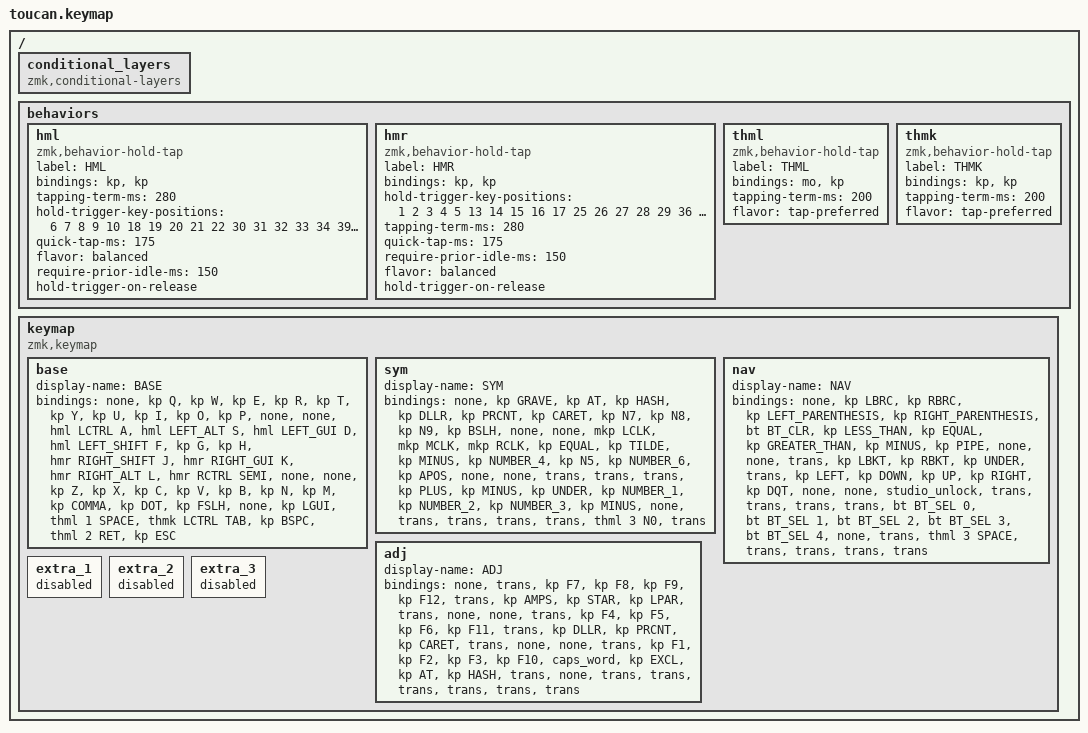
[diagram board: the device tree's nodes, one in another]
#include <behaviors.dtsi>
#include <dt-bindings/zmk/bt.h>
#include <dt-bindings/zmk/keys.h>
#include <dt-bindings/zmk/pointing.h>

#define BASE 0
#define NAV  1
#define SYM  2
#define ADJ  3

/ {
    conditional_layers { compatible = "zmk,conditional-layers"; };

    behaviors {
        hml: hml {
            compatible = "zmk,behavior-hold-tap";
            label = "HML";
            bindings = <&kp>, <&kp>;

            #binding-cells = <2>;
            tapping-term-ms = <280>;
            hold-trigger-key-positions = <6 7 8 9 10 18 19 20 21 22 30 31 32 33 34 39 40 41>;
            quick-tap-ms = <175>;
            flavor = "balanced";
            require-prior-idle-ms = <150>;
            hold-trigger-on-release;
        };

        hmr: hmr {
            compatible = "zmk,behavior-hold-tap";
            label = "HMR";
            bindings = <&kp>, <&kp>;

            #binding-cells = <2>;
            hold-trigger-key-positions = <1 2 3 4 5 13 14 15 16 17 25 26 27 28 29 36 37 38>;
            tapping-term-ms = <280>;
            quick-tap-ms = <175>;
            require-prior-idle-ms = <150>;
            flavor = "balanced";
            hold-trigger-on-release;
        };

        thml: thml {
            compatible = "zmk,behavior-hold-tap";
            label = "THML";
            bindings = <&mo>, <&kp>;

            #binding-cells = <2>;
            tapping-term-ms = <200>;
            flavor = "tap-preferred";
        };

        thmk: thmk {
            compatible = "zmk,behavior-hold-tap";
            label = "THMK";
            bindings = <&kp>, <&kp>;

            #binding-cells = <2>;
            tapping-term-ms = <200>;
            flavor = "tap-preferred";
        };
    };

    keymap {
        compatible = "zmk,keymap";

        base {
            display-name = "BASE";
            bindings = <
&none  &kp Q  &kp W  &kp E  &kp R  &kp T  &kp Y  &kp U  &kp I  &kp O  &kp P  &none  &none  &hml LCTRL A  &hml LEFT_ALT S  &hml LEFT_GUI D  &hml LEFT_SHIFT F  &kp G  &kp H  &hmr RIGHT_SHIFT J  &hmr RIGHT_GUI K  &hmr RIGHT_ALT L  &hmr RCTRL SEMI  &none  &none  &kp Z  &kp X  &kp C  &kp V  &kp B  &kp N  &kp M  &kp COMMA  &kp DOT  &kp FSLH  &none  &kp LGUI  &thml 1 SPACE  &thmk LCTRL TAB  &kp BSPC  &thml 2 RET  &kp ESC
            >;
        };

        sym {
            display-name = "SYM";
            bindings = <
&none  &kp GRAVE  &kp AT  &kp HASH  &kp DLLR  &kp PRCNT  &kp CARET  &kp N7  &kp N8  &kp N9  &kp BSLH  &none  &none  &mkp LCLK  &mkp MCLK  &mkp RCLK  &kp EQUAL  &kp TILDE  &kp MINUS  &kp NUMBER_4  &kp N5  &kp NUMBER_6  &kp APOS  &none  &none  &trans  &trans  &trans  &kp PLUS  &kp MINUS  &kp UNDER  &kp NUMBER_1  &kp NUMBER_2  &kp NUMBER_3  &kp MINUS  &none  &trans  &trans  &trans  &trans  &thml 3 N0  &trans
            >;
        };

        nav {
            display-name = "NAV";
            bindings = <
&none  &kp LBRC  &kp RBRC  &kp LEFT_PARENTHESIS  &kp RIGHT_PARENTHESIS  &bt BT_CLR  &kp LESS_THAN  &kp EQUAL  &kp GREATER_THAN  &kp MINUS  &kp PIPE  &none  &none  &trans  &kp LBKT  &kp RBKT  &kp UNDER  &trans  &kp LEFT  &kp DOWN  &kp UP  &kp RIGHT  &kp DQT  &none  &none  &studio_unlock  &trans  &trans  &trans  &trans  &bt BT_SEL 0  &bt BT_SEL 1  &bt BT_SEL 2  &bt BT_SEL 3  &bt BT_SEL 4  &none  &trans  &thml 3 SPACE  &trans  &trans  &trans  &trans
            >;
        };

        adj {
            display-name = "ADJ";
            bindings = <
&none  &trans  &kp F7  &kp F8  &kp F9  &kp F12  &trans  &kp AMPS  &kp STAR  &kp LPAR  &trans  &none  &none  &trans  &kp F4  &kp F5  &kp F6  &kp F11  &trans  &kp DLLR  &kp PRCNT  &kp CARET  &trans  &none  &none  &trans  &kp F1  &kp F2  &kp F3  &kp F10  &caps_word  &kp EXCL  &kp AT  &kp HASH  &trans  &none  &trans  &trans  &trans  &trans  &trans  &trans
            >;
        };

        extra_1 { status = "reserved"; };

        extra_2 { status = "reserved"; };

        extra_3 { status = "reserved"; };
    };
};
